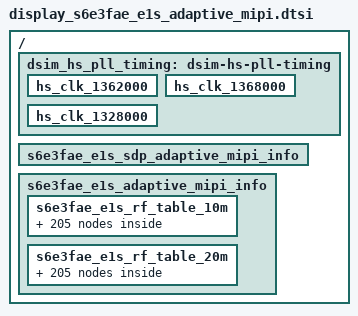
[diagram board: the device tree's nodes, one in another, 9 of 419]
/*
 * SAMSUNG Panel Device Tree Source
 *
 * Copyright (c) Samsung Electronics Co., Ltd.
 *		http://www.samsung.com
 *
 * This program is free software; you can redistribute it and/or modify
 * it under the terms of the GNU General Public License version 2 as
 * published by the Free Software Foundation.
 */

#include <dt-bindings/display/rf-band-id.h>

/ {
	fragment@freq_hop {
		target-path = "/";
		__overlay__ {
			dsim_hs_pll_timing: dsim-hs-pll-timing {
				hs_clk_1362000 {
					pmsk = <
						0x5 0x59 0x0 0xAC00
						0x00 0x00 0x0 0x0
						0x0 0x0 0x0 0x0
						0x0 0x0
						>;
					hs_clk = <1362000>;
				};

				hs_clk_1368000 {
					pmsk = <
						0x5 0x59 0x0 0x1000
						0x00 0x00 0x0 0x0
						0x0 0x0 0x0 0x0
						0x0 0x0
						>;
					hs_clk = <1368000>;
				};

				hs_clk_1328000 {
					pmsk = <
						0x5 0x56 0x0 0x7555
						0x00 0x00 0x0 0x0
						0x0 0x0 0x0 0x0
						0x0 0x0
						>;
					hs_clk = <1328000>;
				};
			}; 

			s6e3fae_e1s_sdp_adaptive_mipi_info:
			s6e3fae_e1s_sdp_adaptive_mipi_info {
				/* TABLE: ADAPTIVE MIPI V2: MIPI CLOCKS [kbps] */
				ADAPTIVE_MIPI_CLOCKS = <
					  1362000
					  1368000
					  1328000
				>;

				/* TABLE: ADAPTIVE MIPI V2: OSC CLOCKS [khz] */
				ADAPTIVE_OSC_CLOCKS = <
					  96500
					  94500
				>;

				/* TABLE: ADAPTIVE MIPI V2: TABLE_10M */
				/* RAT BAND FROM END RATING_A RATING_B RATING_C */
				ADAPTIVE_MIPI_V2_CLK_SEL_TABLE_10M = <
					1	1	0	0	0	0	0
					1	2	0	0	0	0	0
					1	3	0	0	0	63	0
					1	4	0	0	0	0	63
					2	11	10562	10754	0	0	0
					2	11	10755	10824	0	0	60
					2	11	10825	10838	0	0	0
					2	12	9662	9924	0	0	0
					2	12	9925	9938	0	0	60
					2	13	1162	1219	0	0	0
					2	13	1220	1289	0	0	60
					2	13	1290	1453	0	0	0
					2	13	1454	1494	60	0	0
					2	13	1495	1513	60	60	0
					2	14	1537	1729	0	0	0
					2	14	1730	1738	0	0	60
					2	15	4357	4458	0	0	0
					2	16	4387	4413	0	0	0
					2	17	2237	2369	0	0	0
					2	17	2370	2439	0	0	40
					2	17	2440	2563	0	0	0
					2	18	2937	3088	0	0	0
					2	29	712	763	0	0	0
					3	91	0	409	0	0	0
					3	91	410	549	0	0	60
					3	91	550	599	0	0	0
					3	92	600	1149	0	0	0
					3	92	1150	1199	0	0	60
					3	93	1200	1339	0	0	0
					3	93	1340	1479	0	0	60
					3	93	1480	1807	0	0	0
					3	93	1808	1889	60	0	0
					3	93	1890	1947	60	60	0
					3	93	1948	1949	0	60	0
					3	94	1950	2359	0	0	0
					3	94	2360	2399	0	0	60
					3	95	2400	2649	0	0	0
					3	97	2750	3039	0	0	0
					3	97	3040	3179	0	0	40
					3	97	3180	3449	0	0	0
					3	98	3450	3799	0	0	0
					3	102	5010	5179	0	0	0
					3	103	5180	5279	0	0	0
					3	104	5280	5379	0	0	0
					3	107	5730	5849	0	0	0
					3	108	5850	5869	0	140	0
					3	108	5870	5999	0	0	0
					3	109	6000	6149	0	0	0
					3	110	6150	6449	0	0	0
					3	111	6450	6500	0	0	60
					3	111	6501	6599	0	0	0
					3	115	8040	8589	0	0	0
					3	115	8590	8689	0	0	60
					3	116	8690	8719	0	140	0
					3	116	8720	9039	0	0	0
					3	118	9210	9659	0	0	0
					3	119	9660	9769	0	0	0
					3	120	9770	9869	0	0	0
					3	122	9920	10269	0	0	0
					3	122	10270	10359	0	0	60
					3	124	36200	36349	0	0	0
					3	128	37750	37769	0	40	0
					3	128	37770	38249	0	0	0
					3	129	38250	38329	0	60	0
					3	129	38330	38649	0	0	0
					3	130	38650	38819	0	0	0
					3	130	38820	38959	0	0	40
					3	130	38960	39414	0	0	0
					3	130	39415	39519	40	0	0
					3	130	39520	39554	40	40	0
					3	130	39555	39649	0	40	0
					3	131	39650	39659	0	0	40
					3	131	39660	40157	0	0	0
					3	131	40158	40269	40	0	0
					3	131	40270	40297	40	40	0
					3	131	40298	40409	0	40	0
					3	131	40410	41179	0	0	0
					3	131	41180	41319	0	0	40
					3	131	41320	41589	0	0	0
					3	132	41590	41710	40	0	0
					3	132	41711	41720	0	0	0
					3	132	41721	41860	0	40	0
					3	132	41861	42380	0	0	0
					3	132	42381	42520	0	0	40
					3	132	42521	43272	0	0	0
					3	132	43273	43412	40	0	0
					3	132	43413	43430	0	0	0
					3	132	43431	43570	0	40	0
					3	132	43571	43589	0	0	0
					3	138	55240	55422	0	0	0
					3	138	55423	55562	40	0	0
					3	138	55563	55580	0	0	0
					3	138	55581	55720	0	40	0
					3	138	55721	56190	0	0	0
					3	138	56191	56330	0	0	40
					3	138	56331	56739	0	0	0
					3	156	66436	66845	0	0	0
					3	156	66846	66985	0	0	60
					3	156	66986	67335	0	0	0
					3	161	68586	68935	0	0	0
					4	51	0	0	0	0	0
					4	52	0	0	27	63	0
					4	53	0	0	0	0	0
					4	54	0	0	0	69	0
					4	55	0	0	0	42	4
					4	56	0	0	0	63	0
					5	61	0	0	0	0	0
					5	62	0	0	0	0	63
					5	71	0	0	147	294	0
					7	256	422000	430180	0	0	0
					7	256	430181	432980	0	0	60
					7	256	432981	433980	0	0	0
					7	257	386000	396980	0	0	0
					7	257	396981	397980	0	0	60
					7	258	361000	363780	0	0	0
					7	258	363781	366580	0	0	60
					7	258	366581	373140	0	0	0
					7	258	373141	374780	60	0	0
					7	258	374781	375940	60	60	0
					7	258	375941	375980	0	60	0
					7	260	173800	178780	0	0	0
					7	262	524000	529780	0	0	0
					7	262	529781	532580	0	0	40
					7	262	532581	538000	0	0	0
					7	263	185000	191980	0	0	0
					7	267	145800	149200	0	0	0
					7	268	149200	151200	0	0	0
					7	269	151600	153580	0	0	0
					7	273	172000	172380	0	140	0
					7	273	172381	175000	0	0	0
					7	275	158200	164180	0	0	0
					7	280	386000	396980	0	0	0
					7	280	396981	398980	0	0	60
					7	281	171800	172380	0	140	0
					7	281	172381	178800	0	0	0
					7	283	151600	160580	0	0	0
					7	284	143400	145580	0	0	0
					7	285	470000	471980	0	0	0
					7	293	514000	514380	0	40	0
					7	293	514381	523980	0	0	0
					7	294	376000	377580	0	60	0
					7	294	377581	384000	0	0	0
					7	295	460000	463380	0	0	0
					7	295	463381	466180	0	0	40
					7	295	466181	475280	0	0	0
					7	295	475281	477380	40	0	0
					7	295	477381	478080	40	40	0
					7	295	478081	480000	0	40	0
					7	296	499200	499380	0	0	40
					7	296	499381	509340	0	0	0
					7	296	509341	511580	40	0	0
					7	296	511581	512140	40	40	0
					7	296	512141	514380	0	40	0
					7	296	514381	529780	0	0	0
					7	296	529781	532580	0	0	40
					7	296	532581	537980	0	0	0
					7	303	636667	637867	0	0	0
					7	303	637868	638807	20	0	0
					7	303	638808	638927	0	0	0
					7	303	638928	639847	0	20	0
					7	303	639848	642987	0	0	0
					7	303	642988	643927	0	0	20
					7	303	643928	646666	0	0	0
					7	321	422000	430180	0	0	0
					7	321	430181	432980	0	0	60
					7	321	432981	439980	0	0	0
					7	326	123400	130380	0	0	0
					7	332	620000	620860	0	0	0
					7	332	620861	621780	0	0	20
					7	332	621781	626520	0	0	0
					7	332	626521	627460	20	0	0
					7	332	627461	627520	0	0	0
					7	332	627521	628460	0	20	0
					7	332	628461	631920	0	0	0
					7	332	631921	632860	0	0	20
					7	332	632861	637880	0	0	0
					7	332	637881	638800	20	0	0
					7	332	638801	638920	0	0	0
					7	332	638921	639860	0	20	0
					7	332	639861	643000	0	0	0
					7	332	643001	643920	0	0	20
					7	332	643921	649220	0	0	0
					7	332	649221	650160	20	0	0
					7	332	650161	650320	0	0	0
					7	332	650321	651260	0	20	0
					7	332	651261	654060	0	0	0
					7	332	654061	654980	0	0	20
					7	332	654981	660580	0	0	0
					7	332	660581	661500	20	0	0
					7	332	661501	661720	0	0	0
					7	332	661721	662660	0	20	0
					7	332	662661	665120	0	0	0
					7	332	665121	666060	0	0	20
					7	332	666061	671920	0	0	0
					7	332	671921	672860	20	0	0
					7	332	672861	673120	0	0	0
					7	332	673121	674060	0	20	0
					7	332	674061	676200	0	0	0
					7	332	676201	677120	0	0	20
					7	332	677121	680000	0	0	0
					7	333	620000	620860	0	0	0
					7	333	620861	621780	0	0	20
					7	333	621781	626520	0	0	0
					7	333	626521	627460	20	0	0
					7	333	627461	627520	0	0	0
					7	333	627521	628460	0	20	0
					7	333	628461	631920	0	0	0
					7	333	631921	632860	0	0	20
					7	333	632861	637880	0	0	0
					7	333	637881	638800	20	0	0
					7	333	638801	638920	0	0	0
					7	333	638921	639860	0	20	0
					7	333	639861	643000	0	0	0
					7	333	643001	643920	0	0	20
					7	333	643921	649220	0	0	0
					7	333	649221	650160	20	0	0
					7	333	650161	650320	0	0	0
					7	333	650321	651260	0	20	0
					7	333	651261	653333	0	0	0
					7	334	693334	694634	0	0	0
					7	334	694635	695554	20	0	0
					7	334	695555	695934	0	0	0
					7	334	695935	696854	0	20	0
					7	334	696855	698334	0	0	0
					7	334	698335	699254	0	0	20
					7	334	699255	705974	0	0	0
					7	334	705975	706914	20	0	0
					7	334	706915	707334	0	0	0
					7	334	707335	708254	0	20	0
					7	334	708255	709394	0	0	0
					7	334	709395	710314	0	0	20
					7	334	710315	717334	0	0	0
					7	334	717335	718254	20	0	0
					7	334	718255	718734	0	0	0
					7	334	718735	719654	0	20	0
					7	334	719655	720454	0	0	0
					7	334	720455	721394	0	0	20
					7	334	721395	728674	0	0	0
					7	334	728675	729614	20	0	0
					7	334	729615	730134	0	0	0
					7	334	730135	731054	0	20	0
					7	334	731055	731534	0	0	0
					7	334	731535	732454	0	0	20
					7	334	732455	733333	0	0	0
					>;

				/* TABLE: ADAPTIVE MIPI V2: TABLE_20M */
				/* RAT BAND FROM END RATING_A RATING_B RATING_C */
				ADAPTIVE_MIPI_V2_CLK_SEL_TABLE_20M = <
					1	1	0	0	0	0	0
					1	2	0	0	0	0	0
					1	3	0	0	0	63	0
					1	4	0	0	0	0	63
					2	11	10562	10754	0	0	0
					2	11	10755	10824	0	0	60
					2	11	10825	10838	0	0	0
					2	12	9662	9924	0	0	0
					2	12	9925	9938	0	0	60
					2	13	1162	1219	0	0	0
					2	13	1220	1289	0	0	60
					2	13	1290	1453	0	0	0
					2	13	1454	1494	60	0	0
					2	13	1495	1513	60	60	0
					2	14	1537	1729	0	0	0
					2	14	1730	1738	0	0	60
					2	15	4357	4458	0	0	0
					2	16	4387	4413	0	0	0
					2	17	2237	2369	0	0	0
					2	17	2370	2439	0	0	40
					2	17	2440	2563	0	0	0
					2	18	2937	3088	0	0	0
					2	29	712	763	0	0	0
					3	91	0	359	0	0	0
					3	91	360	599	0	0	60
					3	92	600	1099	0	0	0
					3	92	1100	1199	0	0	60
					3	93	1200	1289	0	0	0
					3	93	1290	1529	0	0	60
					3	93	1530	1757	0	0	0
					3	93	1758	1839	60	0	0
					3	93	1840	1949	60	60	0
					3	94	1950	2309	0	0	0
					3	94	2310	2399	0	0	60
					3	95	2400	2649	0	0	0
					3	97	2750	2989	0	0	0
					3	97	2990	3229	0	0	40
					3	97	3230	3449	0	0	0
					3	98	3450	3799	0	0	0
					3	102	5010	5179	0	0	0
					3	103	5180	5279	0	0	0
					3	104	5280	5379	0	0	0
					3	107	5730	5849	0	0	0
					3	108	5850	5882	140	140	0
					3	108	5883	5919	0	140	0
					3	108	5920	5999	0	0	0
					3	109	6000	6149	0	0	0
					3	110	6150	6419	0	0	0
					3	110	6420	6449	0	0	140
					3	111	6450	6550	0	0	60
					3	111	6551	6599	0	0	0
					3	115	8040	8539	0	0	0
					3	115	8540	8689	0	0	60
					3	116	8690	8732	140	140	0
					3	116	8733	8769	0	140	0
					3	116	8770	9039	0	0	0
					3	118	9210	9659	0	0	0
					3	119	9660	9769	0	0	0
					3	120	9770	9869	0	0	0
					3	122	9920	10219	0	0	0
					3	122	10220	10359	0	0	60
					3	124	36200	36349	0	0	0
					3	128	37750	37819	0	40	0
					3	128	37820	38249	0	0	0
					3	129	38250	38297	60	60	0
					3	129	38298	38379	0	60	0
					3	129	38380	38649	0	0	0
					3	130	38650	38769	0	0	0
					3	130	38770	39009	0	0	40
					3	130	39010	39364	0	0	0
					3	130	39365	39469	40	0	0
					3	130	39470	39604	40	40	0
					3	130	39605	39649	0	40	0
					3	131	39650	39709	0	0	40
					3	131	39710	40107	0	0	0
					3	131	40108	40219	40	0	0
					3	131	40220	40347	40	40	0
					3	131	40348	40459	0	40	0
					3	131	40460	41129	0	0	0
					3	131	41130	41369	0	0	40
					3	131	41370	41589	0	0	0
					3	132	41590	41670	40	0	0
					3	132	41671	41760	40	40	0
					3	132	41761	41910	0	40	0
					3	132	41911	42330	0	0	0
					3	132	42331	42570	0	0	40
					3	132	42571	43222	0	0	0
					3	132	43223	43380	40	0	0
					3	132	43381	43462	40	40	0
					3	132	43463	43589	0	40	0
					3	138	55240	55372	0	0	0
					3	138	55373	55530	40	0	0
					3	138	55531	55612	40	40	0
					3	138	55613	55770	0	40	0
					3	138	55771	56140	0	0	0
					3	138	56141	56380	0	0	40
					3	138	56381	56739	0	0	0
					3	156	66436	66795	0	0	0
					3	156	66796	67035	0	0	60
					3	156	67036	67335	0	0	0
					3	161	68586	68935	0	0	0
					4	51	0	0	0	0	0
					4	52	0	0	27	63	0
					4	53	0	0	0	0	0
					4	54	0	0	6	69	0
					4	55	0	0	0	42	4
					4	56	0	0	0	63	0
					5	61	0	0	0	0	0
					5	62	0	0	0	0	63
					5	71	0	0	147	294	0
					7	256	422000	429180	0	0	0
					7	256	429181	433980	0	0	60
					7	257	386000	395980	0	0	0
					7	257	395981	397980	0	0	60
					7	258	361000	362780	0	0	0
					7	258	362781	367580	0	0	60
					7	258	367581	372140	0	0	0
					7	258	372141	373780	60	0	0
					7	258	373781	375980	60	60	0
					7	260	173800	178780	0	0	0
					7	262	524000	528780	0	0	0
					7	262	528781	533580	0	0	40
					7	262	533581	538000	0	0	0
					7	263	185000	191980	0	0	0
					7	267	145800	149200	0	0	0
					7	268	149200	151200	0	0	0
					7	269	151600	153580	0	0	0
					7	273	172000	172640	140	140	0
					7	273	172641	173380	0	140	0
					7	273	173381	175000	0	0	0
					7	275	158200	163580	0	0	0
					7	275	163581	164180	0	0	140
					7	280	386000	395980	0	0	0
					7	280	395981	398980	0	0	60
					7	281	171800	172640	140	140	0
					7	281	172641	173380	0	140	0
					7	281	173381	178800	0	0	0
					7	283	151600	160580	0	0	0
					7	284	143400	145580	0	0	0
					7	285	470000	471980	0	0	0
					7	293	514000	515380	0	40	0
					7	293	515381	523980	0	0	0
					7	294	376000	376940	60	60	0
					7	294	376941	378580	0	60	0
					7	294	378581	384000	0	0	0
					7	295	460000	462380	0	0	0
					7	295	462381	467180	0	0	40
					7	295	467181	474280	0	0	0
					7	295	474281	476380	40	0	0
					7	295	476381	479080	40	40	0
					7	295	479081	480000	0	40	0
					7	296	499200	500380	0	0	40
					7	296	500381	508340	0	0	0
					7	296	508341	510580	40	0	0
					7	296	510581	513140	40	40	0
					7	296	513141	515380	0	40	0
					7	296	515381	528780	0	0	0
					7	296	528781	533580	0	0	40
					7	296	533581	537980	0	0	0
					7	303	636667	637547	0	0	0
					7	303	637548	638587	20	0	0
					7	303	638588	639147	20	20	0
					7	303	639148	640187	0	20	0
					7	303	640188	642667	0	0	0
					7	303	642668	644247	0	0	20
					7	303	644248	646666	0	0	0
					7	321	422000	429180	0	0	0
					7	321	429181	433980	0	0	60
					7	321	433981	439980	0	0	0
					7	326	123400	130380	0	0	0
					7	332	620000	620520	0	0	0
					7	332	620521	622120	0	0	20
					7	332	622121	626200	0	0	0
					7	332	626201	627200	20	0	0
					7	332	627201	627780	20	20	0
					7	332	627781	628780	0	20	0
					7	332	628781	631600	0	0	0
					7	332	631601	633180	0	0	20
					7	332	633181	637540	0	0	0
					7	332	637541	638600	20	0	0
					7	332	638601	639140	20	20	0
					7	332	639141	640180	0	20	0
					7	332	640181	642660	0	0	0
					7	332	642661	644260	0	0	20
					7	332	644261	648900	0	0	0
					7	332	648901	650000	20	0	0
					7	332	650001	650480	20	20	0
					7	332	650481	651580	0	20	0
					7	332	651581	653720	0	0	0
					7	332	653721	655320	0	0	20
					7	332	655321	660240	0	0	0
					7	332	660241	661400	20	0	0
					7	332	661401	661840	20	20	0
					7	332	661841	662980	0	20	0
					7	332	662981	664800	0	0	0
					7	332	664801	666380	0	0	20
					7	332	666381	671600	0	0	0
					7	332	671601	672800	20	0	0
					7	332	672801	673180	20	20	0
					7	332	673181	674380	0	20	0
					7	332	674381	675860	0	0	0
					7	332	675861	677460	0	0	20
					7	332	677461	680000	0	0	0
					7	333	620000	620520	0	0	0
					7	333	620521	622120	0	0	20
					7	333	622121	626200	0	0	0
					7	333	626201	627200	20	0	0
					7	333	627201	627780	20	20	0
					7	333	627781	628780	0	20	0
					7	333	628781	631600	0	0	0
					7	333	631601	633180	0	0	20
					7	333	633181	637540	0	0	0
					7	333	637541	638600	20	0	0
					7	333	638601	639140	20	20	0
					7	333	639141	640180	0	20	0
					7	333	640181	642660	0	0	0
					7	333	642661	644260	0	0	20
					7	333	644261	648900	0	0	0
					7	333	648901	650000	20	0	0
					7	333	650001	650480	20	20	0
					7	333	650481	651580	0	20	0
					7	333	651581	653333	0	0	0
					7	334	693334	694294	0	0	0
					7	334	694295	695594	20	0	0
					7	334	695595	695894	20	20	0
					7	334	695895	697194	0	20	0
					7	334	697195	697994	0	0	0
					7	334	697995	699594	0	0	20
					7	334	699595	705634	0	0	0
					7	334	705635	706994	20	0	0
					7	334	706995	707234	20	20	0
					7	334	707235	708594	0	20	0
					7	334	708595	709054	0	0	0
					7	334	709055	710654	0	0	20
					7	334	710655	716994	0	0	0
					7	334	716995	718394	20	0	0
					7	334	718395	718594	20	20	0
					7	334	718595	719994	0	20	0
					7	334	719995	720134	0	0	0
					7	334	720135	721714	0	0	20
					7	334	721715	728334	0	0	0
					7	334	728335	729794	20	0	0
					7	334	729795	729934	20	20	0
					7	334	729935	731194	0	20	0
					7	334	731195	731394	0	20	20
					7	334	731395	732794	0	0	20
					7	334	732795	733333	0	0	0
					>;

				/* TABLE: ADAPTIVE MIPI V2: TABLE_OSC */
				/* RAT BAND FROM END OSC_IDX */
				ADAPTIVE_MIPI_V2_CLK_SEL_TABLE_OSC = <
					3	95	2400	2534	1
					3	98	3710	3799	1
					3	104	5280	5379	1
					3	108	5850	5999	1
					3	109	6000	6074	1
					3	116	8690	8924	1
					3	118	9210	9489	1
					7	260	175220	176480	1
					7	263	190181	191980	1
					7	269	151600	153580	1
					7	283	151600	157180	1
					>;
			};

			s6e3fae_e1s_adaptive_mipi_info:
			s6e3fae_e1s_adaptive_mipi_info {
				mipi_freq_lists = <1362 1368 1328>;
				ddi_osc_freq_lists = <1813>;
				rf_table_lists = <&s6e3fae_e1s_rf_table_10m &s6e3fae_e1s_rf_table_20m>;

				s6e3fae_e1s_rf_table_10m:
				s6e3fae_e1s_rf_table_10m {
					tb1 { id = <GSM850>; range = <0 0>; rating = <0 0 0>; };
					tb2 { id = <EGSM900>; range = <0 0>; rating = <0 0 0>; };
					tb3 { id = <DCS1800>; range = <0 0>; rating = <0 4 0>; };
					tb4 { id = <PCS1900>; range = <0 0>; rating = <0 0 80>; };
					tb5 { id = <WB01>; range = <10562 10754>; rating = <0 0 0>; };
					tb6 { id = <WB01>; range = <10755 10824>; rating = <0 0 4>; };
					tb7 { id = <WB01>; range = <10825 10838>; rating = <0 0 0>; };
					tb8 { id = <WB02>; range = <9662 9924>; rating = <0 0 0>; };
					tb9 { id = <WB02>; range = <9925 9938>; rating = <0 0 80>; };
					tb10 { id = <WB03>; range = <1162 1219>; rating = <0 0 0>; };
					tb11 { id = <WB03>; range = <1220 1289>; rating = <0 0 4>; };
					tb12 { id = <WB03>; range = <1290 1453>; rating = <0 0 0>; };
					tb13 { id = <WB03>; range = <1454 1494>; rating = <4 0 0>; };
					tb14 { id = <WB03>; range = <1495 1513>; rating = <4 4 0>; };
					tb15 { id = <WB04>; range = <1537 1729>; rating = <0 0 0>; };
					tb16 { id = <WB04>; range = <1730 1738>; rating = <0 0 4>; };
					tb17 { id = <WB05>; range = <4357 4458>; rating = <0 0 0>; };
					tb18 { id = <WB06>; range = <4387 4413>; rating = <0 0 0>; };
					tb19 { id = <WB07>; range = <2237 2369>; rating = <0 0 0>; };
					tb20 { id = <WB07>; range = <2370 2439>; rating = <0 0 40>; };
					tb21 { id = <WB07>; range = <2440 2563>; rating = <0 0 0>; };
					tb22 { id = <WB08>; range = <2937 3088>; rating = <0 0 0>; };
					tb23 { id = <WB19>; range = <712 763>; rating = <0 0 0>; };
					tb24 { id = <LB01>; range = <0 409>; rating = <0 0 0>; };
					tb25 { id = <LB01>; range = <410 549>; rating = <0 0 4>; };
					tb26 { id = <LB01>; range = <550 599>; rating = <0 0 0>; };
					tb27 { id = <LB02>; range = <600 1149>; rating = <0 0 0>; };
					tb28 { id = <LB02>; range = <1150 1199>; rating = <0 0 80>; };
					tb29 { id = <LB03>; range = <1200 1339>; rating = <0 0 0>; };
					tb30 { id = <LB03>; range = <1340 1479>; rating = <0 0 4>; };
					tb31 { id = <LB03>; range = <1480 1807>; rating = <0 0 0>; };
					tb32 { id = <LB03>; range = <1808 1889>; rating = <4 0 0>; };
					tb33 { id = <LB03>; range = <1890 1947>; rating = <4 4 0>; };
					tb34 { id = <LB03>; range = <1948 1949>; rating = <0 4 0>; };
					tb35 { id = <LB04>; range = <1950 2359>; rating = <0 0 0>; };
					tb36 { id = <LB04>; range = <2360 2399>; rating = <0 0 4>; };
					tb37 { id = <LB05>; range = <2400 2649>; rating = <0 0 0>; };
					tb38 { id = <LB07>; range = <2750 3039>; rating = <0 0 0>; };
					tb39 { id = <LB07>; range = <3040 3179>; rating = <0 0 40>; };
					tb40 { id = <LB07>; range = <3180 3449>; rating = <0 0 0>; };
					tb41 { id = <LB08>; range = <3450 3799>; rating = <0 0 0>; };
					tb42 { id = <LB12>; range = <5010 5179>; rating = <0 0 0>; };
					tb43 { id = <LB13>; range = <5180 5279>; rating = <0 0 0>; };
					tb44 { id = <LB14>; range = <5280 5379>; rating = <0 0 0>; };
					tb45 { id = <LB17>; range = <5730 5849>; rating = <0 0 0>; };
					tb46 { id = <LB18>; range = <5850 5869>; rating = <0 6 0>; };
					tb47 { id = <LB18>; range = <5870 5999>; rating = <0 0 0>; };
					tb48 { id = <LB19>; range = <6000 6149>; rating = <0 0 0>; };
					tb49 { id = <LB20>; range = <6150 6449>; rating = <0 0 0>; };
					tb50 { id = <LB21>; range = <6450 6500>; rating = <0 0 4>; };
					tb51 { id = <LB21>; range = <6501 6599>; rating = <0 0 0>; };
					tb52 { id = <LB25>; range = <8040 8589>; rating = <0 0 0>; };
					tb53 { id = <LB25>; range = <8590 8689>; rating = <0 0 80>; };
					tb54 { id = <LB26>; range = <8690 8719>; rating = <0 6 0>; };
					tb55 { id = <LB26>; range = <8720 9039>; rating = <0 0 0>; };
					tb56 { id = <LB28>; range = <9210 9659>; rating = <0 0 0>; };
					tb57 { id = <LB29>; range = <9660 9769>; rating = <0 0 0>; };
					tb58 { id = <LB30>; range = <9770 9869>; rating = <0 0 0>; };
					tb59 { id = <LB32>; range = <9920 10269>; rating = <0 0 0>; };
					tb60 { id = <LB32>; range = <10270 10359>; rating = <0 0 4>; };
					tb61 { id = <LB34>; range = <36200 36349>; rating = <0 0 0>; };
					tb62 { id = <LB38>; range = <37750 37769>; rating = <0 2 0>; };
					tb63 { id = <LB38>; range = <37770 38249>; rating = <0 0 0>; };
					tb64 { id = <LB39>; range = <38250 38329>; rating = <0 4 0>; };
					tb65 { id = <LB39>; range = <38330 38649>; rating = <0 0 0>; };
					tb66 { id = <LB40>; range = <38650 39649>; rating = <0 0 0>; };
					tb67 { id = <LB41>; range = <39650 39659>; rating = <0 0 2>; };
					tb68 { id = <LB41>; range = <39660 40157>; rating = <0 0 0>; };
					tb69 { id = <LB41>; range = <40158 40269>; rating = <2 0 0>; };
					tb70 { id = <LB41>; range = <40270 40297>; rating = <2 2 0>; };
					tb71 { id = <LB41>; range = <40298 40409>; rating = <0 2 0>; };
					tb72 { id = <LB41>; range = <40410 41179>; rating = <0 0 0>; };
					tb73 { id = <LB41>; range = <41180 41319>; rating = <0 0 40>; };
					tb74 { id = <LB41>; range = <41320 41589>; rating = <0 0 0>; };
					tb75 { id = <LB42>; range = <41590 41710>; rating = <40 0 0>; };
					tb76 { id = <LB42>; range = <41711 41720>; rating = <0 0 0>; };
					tb77 { id = <LB42>; range = <41721 41860>; rating = <0 40 0>; };
					tb78 { id = <LB42>; range = <41861 42380>; rating = <0 0 0>; };
					tb79 { id = <LB42>; range = <42381 42520>; rating = <0 0 2>; };
					tb80 { id = <LB42>; range = <42521 43272>; rating = <0 0 0>; };
					tb81 { id = <LB42>; range = <43273 43412>; rating = <2 0 0>; };
					tb82 { id = <LB42>; range = <43413 43430>; rating = <0 0 0>; };
					tb83 { id = <LB42>; range = <43431 43570>; rating = <0 2 0>; };
					tb84 { id = <LB42>; range = <43571 43589>; rating = <0 0 0>; };
					tb85 { id = <LB48>; range = <55240 55422>; rating = <0 0 0>; };
					tb86 { id = <LB48>; range = <55423 55562>; rating = <2 0 0>; };
					tb87 { id = <LB48>; range = <55563 55580>; rating = <0 0 0>; };
					tb88 { id = <LB48>; range = <55581 55720>; rating = <0 2 0>; };
					tb89 { id = <LB48>; range = <55721 56739>; rating = <0 0 0>; };
					tb90 { id = <LB66>; range = <66436 66845>; rating = <0 0 0>; };
					tb91 { id = <LB66>; range = <66846 66985>; rating = <0 0 4>; };
					tb92 { id = <LB66>; range = <66986 67335>; rating = <0 0 0>; };
					tb93 { id = <LB71>; range = <68586 68935>; rating = <0 0 0>; };
					tb94 { id = <TD1>; range = <0 0>; rating = <0 0 0>; };
					tb95 { id = <TD2>; range = <0 0>; rating = <2 4 0>; };
					tb96 { id = <TD3>; range = <0 0>; rating = <0 0 0>; };
					tb97 { id = <TD4>; range = <0 0>; rating = <0 6 0>; };
					tb98 { id = <TD5>; range = <0 0>; rating = <0 0 1>; };
					tb99 { id = <TD6>; range = <0 0>; rating = <0 4 0>; };
					tb100 { id = <BC0>; range = <0 0>; rating = <0 0 0>; };
					tb101 { id = <BC1>; range = <0 0>; rating = <0 0 80>; };
					tb102 { id = <BC10>; range = <0 0>; rating = <6 12 0>; };
					tb103 { id = <N001>; range = <422000 430180>; rating = <0 0 0>; };
					tb104 { id = <N001>; range = <430181 432980>; rating = <0 0 4>; };
					tb105 { id = <N001>; range = <432981 433980>; rating = <0 0 0>; };
					tb106 { id = <N002>; range = <386000 396980>; rating = <0 0 0>; };
					tb107 { id = <N002>; range = <396981 397980>; rating = <0 0 80>; };
					tb108 { id = <N003>; range = <361000 363780>; rating = <0 0 0>; };
					tb109 { id = <N003>; range = <363781 366580>; rating = <0 0 4>; };
					tb110 { id = <N003>; range = <366581 373140>; rating = <0 0 0>; };
					tb111 { id = <N003>; range = <373141 374780>; rating = <4 0 0>; };
					tb112 { id = <N003>; range = <374781 375940>; rating = <4 4 0>; };
					tb113 { id = <N003>; range = <375941 375980>; rating = <0 4 0>; };
					tb114 { id = <N005>; range = <173800 178780>; rating = <0 0 0>; };
					tb115 { id = <N007>; range = <524000 529780>; rating = <0 0 0>; };
					tb116 { id = <N007>; range = <529781 532580>; rating = <0 0 40>; };
					tb117 { id = <N007>; range = <532581 538000>; rating = <0 0 0>; };
					tb118 { id = <N008>; range = <185000 191980>; rating = <0 0 0>; };
					tb119 { id = <N012>; range = <145800 149200>; rating = <0 0 0>; };
					tb120 { id = <N014>; range = <151600 153580>; rating = <0 0 0>; };
					tb121 { id = <N020>; range = <158200 164180>; rating = <0 0 0>; };
					tb122 { id = <N025>; range = <386000 396980>; rating = <0 0 0>; };
					tb123 { id = <N025>; range = <396981 398980>; rating = <0 0 80>; };
					tb124 { id = <N028>; range = <151600 160580>; rating = <0 0 0>; };
					tb125 { id = <N029>; range = <143400 145580>; rating = <0 0 0>; };
					tb126 { id = <N030>; range = <470000 471980>; rating = <0 0 0>; };
					tb127 { id = <N038>; range = <514000 514380>; rating = <0 2 0>; };
					tb128 { id = <N038>; range = <514381 523980>; rating = <0 0 0>; };
					tb129 { id = <N040>; range = <460000 480000>; rating = <0 0 0>; };
					tb130 { id = <N041>; range = <499200 499380>; rating = <0 0 2>; };
					tb131 { id = <N041>; range = <499381 509340>; rating = <0 0 0>; };
					tb132 { id = <N041>; range = <509341 511580>; rating = <2 0 0>; };
					tb133 { id = <N041>; range = <511581 512140>; rating = <2 2 0>; };
					tb134 { id = <N041>; range = <512141 514380>; rating = <0 2 0>; };
					tb135 { id = <N041>; range = <514381 529780>; rating = <0 0 0>; };
					tb136 { id = <N041>; range = <529781 532580>; rating = <0 0 40>; };
					tb137 { id = <N041>; range = <532581 537980>; rating = <0 0 0>; };
					tb138 { id = <N048>; range = <636667 637867>; rating = <0 0 0>; };
					tb139 { id = <N048>; range = <637868 638807>; rating = <2 0 0>; };
					tb140 { id = <N048>; range = <638808 638927>; rating = <0 0 0>; };
					tb141 { id = <N048>; range = <638928 639847>; rating = <0 2 0>; };
					tb142 { id = <N048>; range = <639848 646666>; rating = <0 0 0>; };
					tb143 { id = <N066>; range = <422000 430180>; rating = <0 0 0>; };
					tb144 { id = <N066>; range = <430181 432980>; rating = <0 0 4>; };
					tb145 { id = <N066>; range = <432981 439980>; rating = <0 0 0>; };
					tb146 { id = <N071>; range = <123400 130380>; rating = <0 0 0>; };
					tb147 { id = <N077>; range = <620000 620860>; rating = <0 0 0>; };
					tb148 { id = <N077>; range = <620861 621780>; rating = <0 0 40>; };
					tb149 { id = <N077>; range = <621781 626520>; rating = <0 0 0>; };
					tb150 { id = <N077>; range = <626521 627460>; rating = <40 0 0>; };
					tb151 { id = <N077>; range = <627461 627520>; rating = <0 0 0>; };
					tb152 { id = <N077>; range = <627521 628460>; rating = <0 40 0>; };
					tb153 { id = <N077>; range = <628461 631920>; rating = <0 0 0>; };
					tb154 { id = <N077>; range = <631921 632860>; rating = <0 0 2>; };
					tb155 { id = <N077>; range = <632861 637880>; rating = <0 0 0>; };
					tb156 { id = <N077>; range = <637881 638800>; rating = <2 0 0>; };
					tb157 { id = <N077>; range = <638801 638920>; rating = <0 0 0>; };
					tb158 { id = <N077>; range = <638921 639860>; rating = <0 2 0>; };
					tb159 { id = <N077>; range = <639861 654060>; rating = <0 0 0>; };
					tb160 { id = <N077>; range = <654061 654980>; rating = <0 0 2>; };
					tb161 { id = <N077>; range = <654981 660580>; rating = <0 0 0>; };
					tb162 { id = <N077>; range = <660581 661500>; rating = <2 0 0>; };
					tb163 { id = <N077>; range = <661501 661720>; rating = <0 0 0>; };
					tb164 { id = <N077>; range = <661721 662660>; rating = <0 2 0>; };
					tb165 { id = <N077>; range = <662661 665120>; rating = <0 0 0>; };
					tb166 { id = <N077>; range = <665121 666060>; rating = <0 0 40>; };
					tb167 { id = <N077>; range = <666061 671920>; rating = <0 0 0>; };
					tb168 { id = <N077>; range = <671921 672860>; rating = <40 0 0>; };
					tb169 { id = <N077>; range = <672861 673120>; rating = <0 0 0>; };
					tb170 { id = <N077>; range = <673121 674060>; rating = <0 40 0>; };
					tb171 { id = <N077>; range = <674061 676200>; rating = <0 0 0>; };
					tb172 { id = <N077>; range = <676201 677120>; rating = <0 0 2>; };
					tb173 { id = <N077>; range = <677121 680000>; rating = <0 0 0>; };
					tb174 { id = <N078>; range = <620000 620860>; rating = <0 0 0>; };
					tb175 { id = <N078>; range = <620861 621780>; rating = <0 0 40>; };
					tb176 { id = <N078>; range = <621781 626520>; rating = <0 0 0>; };
					tb177 { id = <N078>; range = <626521 627460>; rating = <40 0 0>; };
					tb178 { id = <N078>; range = <627461 627520>; rating = <0 0 0>; };
					tb179 { id = <N078>; range = <627521 628460>; rating = <0 40 0>; };
					tb180 { id = <N078>; range = <628461 631920>; rating = <0 0 0>; };
					tb181 { id = <N078>; range = <631921 632860>; rating = <0 0 2>; };
					tb182 { id = <N078>; range = <632861 637880>; rating = <0 0 0>; };
					tb183 { id = <N078>; range = <637881 638800>; rating = <2 0 0>; };
					tb184 { id = <N078>; range = <638801 638920>; rating = <0 0 0>; };
					tb185 { id = <N078>; range = <638921 639860>; rating = <0 2 0>; };
					tb186 { id = <N078>; range = <639861 653333>; rating = <0 0 0>; };
					tb187 { id = <N079>; range = <693334 698334>; rating = <0 0 0>; };
					tb188 { id = <N079>; range = <698335 699254>; rating = <0 0 2>; };
					tb189 { id = <N079>; range = <699255 705974>; rating = <0 0 0>; };
					tb190 { id = <N079>; range = <705975 706914>; rating = <2 0 0>; };
					tb191 { id = <N079>; range = <706915 707334>; rating = <0 0 0>; };
					tb192 { id = <N079>; range = <707335 708254>; rating = <0 2 0>; };
					tb193 { id = <N079>; range = <708255 709394>; rating = <0 0 0>; };
					tb194 { id = <N079>; range = <709395 710314>; rating = <0 0 40>; };
					tb195 { id = <N079>; range = <710315 717334>; rating = <0 0 0>; };
					tb196 { id = <N079>; range = <717335 718254>; rating = <40 0 0>; };
					tb197 { id = <N079>; range = <718255 718734>; rating = <0 0 0>; };
					tb198 { id = <N079>; range = <718735 719654>; rating = <0 40 0>; };
					tb199 { id = <N079>; range = <719655 720454>; rating = <0 0 0>; };
					tb200 { id = <N079>; range = <720455 721394>; rating = <0 0 2>; };
					tb201 { id = <N079>; range = <721395 728674>; rating = <0 0 0>; };
					tb202 { id = <N079>; range = <728675 729614>; rating = <2 0 0>; };
					tb203 { id = <N079>; range = <729615 730134>; rating = <0 0 0>; };
					tb204 { id = <N079>; range = <730135 731054>; rating = <0 2 0>; };
					tb205 { id = <N079>; range = <731055 733333>; rating = <0 0 0>; };
				};

				s6e3fae_e1s_rf_table_20m:
				s6e3fae_e1s_rf_table_20m {
					tb1 { id = <GSM850>; range = <0 0>; rating = <0 0 0>; };
					tb2 { id = <EGSM900>; range = <0 0>; rating = <0 0 0>; };
					tb3 { id = <DCS1800>; range = <0 0>; rating = <0 4 0>; };
					tb4 { id = <PCS1900>; range = <0 0>; rating = <0 0 80>; };
					tb5 { id = <WB01>; range = <10562 10754>; rating = <0 0 0>; };
					tb6 { id = <WB01>; range = <10755 10824>; rating = <0 0 4>; };
					tb7 { id = <WB01>; range = <10825 10838>; rating = <0 0 0>; };
					tb8 { id = <WB02>; range = <9662 9924>; rating = <0 0 0>; };
					tb9 { id = <WB02>; range = <9925 9938>; rating = <0 0 80>; };
					tb10 { id = <WB03>; range = <1162 1219>; rating = <0 0 0>; };
					tb11 { id = <WB03>; range = <1220 1289>; rating = <0 0 4>; };
					tb12 { id = <WB03>; range = <1290 1453>; rating = <0 0 0>; };
					tb13 { id = <WB03>; range = <1454 1494>; rating = <4 0 0>; };
					tb14 { id = <WB03>; range = <1495 1513>; rating = <4 4 0>; };
					tb15 { id = <WB04>; range = <1537 1729>; rating = <0 0 0>; };
					tb16 { id = <WB04>; range = <1730 1738>; rating = <0 0 4>; };
					tb17 { id = <WB05>; range = <4357 4458>; rating = <0 0 0>; };
					tb18 { id = <WB06>; range = <4387 4413>; rating = <0 0 0>; };
					tb19 { id = <WB07>; range = <2237 2369>; rating = <0 0 0>; };
					tb20 { id = <WB07>; range = <2370 2439>; rating = <0 0 40>; };
					tb21 { id = <WB07>; range = <2440 2563>; rating = <0 0 0>; };
					tb22 { id = <WB08>; range = <2937 3088>; rating = <0 0 0>; };
					tb23 { id = <WB19>; range = <712 763>; rating = <0 0 0>; };
					tb24 { id = <LB01>; range = <0 359>; rating = <0 0 0>; };
					tb25 { id = <LB01>; range = <360 599>; rating = <0 0 4>; };
					tb26 { id = <LB02>; range = <600 1099>; rating = <0 0 0>; };
					tb27 { id = <LB02>; range = <1100 1199>; rating = <0 0 80>; };
					tb28 { id = <LB03>; range = <1200 1289>; rating = <0 0 0>; };
					tb29 { id = <LB03>; range = <1290 1529>; rating = <0 0 4>; };
					tb30 { id = <LB03>; range = <1530 1757>; rating = <0 0 0>; };
					tb31 { id = <LB03>; range = <1758 1839>; rating = <4 0 0>; };
					tb32 { id = <LB03>; range = <1840 1949>; rating = <4 4 0>; };
					tb33 { id = <LB04>; range = <1950 2309>; rating = <0 0 0>; };
					tb34 { id = <LB04>; range = <2310 2399>; rating = <0 0 4>; };
					tb35 { id = <LB05>; range = <2400 2649>; rating = <0 0 0>; };
					tb36 { id = <LB07>; range = <2750 2989>; rating = <0 0 0>; };
					tb37 { id = <LB07>; range = <2990 3229>; rating = <0 0 40>; };
					tb38 { id = <LB07>; range = <3230 3449>; rating = <0 0 0>; };
					tb39 { id = <LB08>; range = <3450 3799>; rating = <0 0 0>; };
					tb40 { id = <LB12>; range = <5010 5179>; rating = <0 0 0>; };
					tb41 { id = <LB13>; range = <5180 5279>; rating = <0 0 0>; };
					tb42 { id = <LB14>; range = <5280 5379>; rating = <0 0 0>; };
					tb43 { id = <LB17>; range = <5730 5849>; rating = <0 0 0>; };
					tb44 { id = <LB18>; range = <5850 5882>; rating = <6 6 0>; };
					tb45 { id = <LB18>; range = <5883 5919>; rating = <0 6 0>; };
					tb46 { id = <LB18>; range = <5920 5999>; rating = <0 0 0>; };
					tb47 { id = <LB19>; range = <6000 6149>; rating = <0 0 0>; };
					tb48 { id = <LB20>; range = <6150 6419>; rating = <0 0 0>; };
					tb49 { id = <LB20>; range = <6420 6449>; rating = <0 0 6>; };
					tb50 { id = <LB21>; range = <6450 6550>; rating = <0 0 4>; };
					tb51 { id = <LB21>; range = <6551 6599>; rating = <0 0 0>; };
					tb52 { id = <LB25>; range = <8040 8539>; rating = <0 0 0>; };
					tb53 { id = <LB25>; range = <8540 8689>; rating = <0 0 80>; };
					tb54 { id = <LB26>; range = <8690 8732>; rating = <6 6 0>; };
					tb55 { id = <LB26>; range = <8733 8769>; rating = <0 6 0>; };
					tb56 { id = <LB26>; range = <8770 9039>; rating = <0 0 0>; };
					tb57 { id = <LB28>; range = <9210 9659>; rating = <0 0 0>; };
					tb58 { id = <LB29>; range = <9660 9769>; rating = <0 0 0>; };
					tb59 { id = <LB30>; range = <9770 9869>; rating = <0 0 0>; };
					tb60 { id = <LB32>; range = <9920 10219>; rating = <0 0 0>; };
					tb61 { id = <LB32>; range = <10220 10359>; rating = <0 0 4>; };
					tb62 { id = <LB34>; range = <36200 36349>; rating = <0 0 0>; };
					tb63 { id = <LB38>; range = <37750 37819>; rating = <0 2 0>; };
					tb64 { id = <LB38>; range = <37820 38249>; rating = <0 0 0>; };
					tb65 { id = <LB39>; range = <38250 38297>; rating = <4 4 0>; };
					tb66 { id = <LB39>; range = <38298 38379>; rating = <0 4 0>; };
					tb67 { id = <LB39>; range = <38380 38649>; rating = <0 0 0>; };
					tb68 { id = <LB40>; range = <38650 39649>; rating = <0 0 0>; };
					tb69 { id = <LB41>; range = <39650 39709>; rating = <0 0 2>; };
					tb70 { id = <LB41>; range = <39710 40107>; rating = <0 0 0>; };
					tb71 { id = <LB41>; range = <40108 40219>; rating = <2 0 0>; };
					tb72 { id = <LB41>; range = <40220 40347>; rating = <2 2 0>; };
					tb73 { id = <LB41>; range = <40348 40459>; rating = <0 2 0>; };
					tb74 { id = <LB41>; range = <40460 41129>; rating = <0 0 0>; };
					tb75 { id = <LB41>; range = <41130 41369>; rating = <0 0 40>; };
					tb76 { id = <LB41>; range = <41370 41589>; rating = <0 0 0>; };
					tb77 { id = <LB42>; range = <41590 41670>; rating = <40 0 0>; };
					tb78 { id = <LB42>; range = <41671 41760>; rating = <40 40 0>; };
					tb79 { id = <LB42>; range = <41761 41910>; rating = <0 40 0>; };
					tb80 { id = <LB42>; range = <41911 42330>; rating = <0 0 0>; };
					tb81 { id = <LB42>; range = <42331 42570>; rating = <0 0 2>; };
					tb82 { id = <LB42>; range = <42571 43222>; rating = <0 0 0>; };
					tb83 { id = <LB42>; range = <43223 43380>; rating = <2 0 0>; };
					tb84 { id = <LB42>; range = <43381 43462>; rating = <2 2 0>; };
					tb85 { id = <LB42>; range = <43463 43589>; rating = <0 2 0>; };
					tb86 { id = <LB48>; range = <55240 55372>; rating = <0 0 0>; };
					tb87 { id = <LB48>; range = <55373 55530>; rating = <2 0 0>; };
					tb88 { id = <LB48>; range = <55531 55612>; rating = <2 2 0>; };
					tb89 { id = <LB48>; range = <55613 55770>; rating = <0 2 0>; };
					tb90 { id = <LB48>; range = <55771 56739>; rating = <0 0 0>; };
					tb91 { id = <LB66>; range = <66436 66795>; rating = <0 0 0>; };
					tb92 { id = <LB66>; range = <66796 67035>; rating = <0 0 4>; };
					tb93 { id = <LB66>; range = <67036 67335>; rating = <0 0 0>; };
					tb94 { id = <LB71>; range = <68586 68935>; rating = <0 0 0>; };
					tb95 { id = <TD1>; range = <0 0>; rating = <0 0 0>; };
					tb96 { id = <TD2>; range = <0 0>; rating = <2 4 0>; };
					tb97 { id = <TD3>; range = <0 0>; rating = <0 0 0>; };
					tb98 { id = <TD4>; range = <0 0>; rating = <2 6 0>; };
					tb99 { id = <TD5>; range = <0 0>; rating = <0 0 1>; };
					tb100 { id = <TD6>; range = <0 0>; rating = <0 4 0>; };
					tb101 { id = <BC0>; range = <0 0>; rating = <0 0 0>; };
					tb102 { id = <BC1>; range = <0 0>; rating = <0 0 80>; };
					tb103 { id = <BC10>; range = <0 0>; rating = <6 12 0>; };
					tb104 { id = <N001>; range = <422000 429180>; rating = <0 0 0>; };
					tb105 { id = <N001>; range = <429181 433980>; rating = <0 0 4>; };
					tb106 { id = <N002>; range = <386000 395980>; rating = <0 0 0>; };
					tb107 { id = <N002>; range = <395981 397980>; rating = <0 0 80>; };
					tb108 { id = <N003>; range = <361000 362780>; rating = <0 0 0>; };
					tb109 { id = <N003>; range = <362781 367580>; rating = <0 0 4>; };
					tb110 { id = <N003>; range = <367581 372140>; rating = <0 0 0>; };
					tb111 { id = <N003>; range = <372141 373780>; rating = <4 0 0>; };
					tb112 { id = <N003>; range = <373781 375980>; rating = <4 4 0>; };
					tb113 { id = <N005>; range = <173800 178780>; rating = <0 0 0>; };
					tb114 { id = <N007>; range = <524000 528780>; rating = <0 0 0>; };
					tb115 { id = <N007>; range = <528781 533580>; rating = <0 0 40>; };
					tb116 { id = <N007>; range = <533581 538000>; rating = <0 0 0>; };
					tb117 { id = <N008>; range = <185000 191980>; rating = <0 0 0>; };
					tb118 { id = <N012>; range = <145800 149200>; rating = <0 0 0>; };
					tb119 { id = <N014>; range = <151600 153580>; rating = <0 0 0>; };
					tb120 { id = <N020>; range = <158200 163580>; rating = <0 0 0>; };
					tb121 { id = <N020>; range = <163581 164180>; rating = <0 0 6>; };
					tb122 { id = <N025>; range = <386000 395980>; rating = <0 0 0>; };
					tb123 { id = <N025>; range = <395981 398980>; rating = <0 0 80>; };
					tb124 { id = <N028>; range = <151600 160580>; rating = <0 0 0>; };
					tb125 { id = <N029>; range = <143400 145580>; rating = <0 0 0>; };
					tb126 { id = <N030>; range = <470000 471980>; rating = <0 0 0>; };
					tb127 { id = <N038>; range = <514000 515380>; rating = <0 2 0>; };
					tb128 { id = <N038>; range = <515381 523980>; rating = <0 0 0>; };
					tb129 { id = <N040>; range = <460000 480000>; rating = <0 0 0>; };
					tb130 { id = <N041>; range = <499200 500380>; rating = <0 0 2>; };
					tb131 { id = <N041>; range = <500381 508340>; rating = <0 0 0>; };
					tb132 { id = <N041>; range = <508341 510580>; rating = <2 0 0>; };
					tb133 { id = <N041>; range = <510581 513140>; rating = <2 2 0>; };
					tb134 { id = <N041>; range = <513141 515380>; rating = <0 2 0>; };
					tb135 { id = <N041>; range = <515381 528780>; rating = <0 0 0>; };
					tb136 { id = <N041>; range = <528781 533580>; rating = <0 0 40>; };
					tb137 { id = <N041>; range = <533581 537980>; rating = <0 0 0>; };
					tb138 { id = <N048>; range = <636667 637547>; rating = <0 0 0>; };
					tb139 { id = <N048>; range = <637548 638587>; rating = <2 0 0>; };
					tb140 { id = <N048>; range = <638588 639147>; rating = <2 2 0>; };
					tb141 { id = <N048>; range = <639148 640187>; rating = <0 2 0>; };
					tb142 { id = <N048>; range = <640188 646666>; rating = <0 0 0>; };
					tb143 { id = <N066>; range = <422000 429180>; rating = <0 0 0>; };
					tb144 { id = <N066>; range = <429181 433980>; rating = <0 0 4>; };
					tb145 { id = <N066>; range = <433981 439980>; rating = <0 0 0>; };
					tb146 { id = <N071>; range = <123400 130380>; rating = <0 0 0>; };
					tb147 { id = <N077>; range = <620000 620520>; rating = <0 0 0>; };
					tb148 { id = <N077>; range = <620521 622120>; rating = <0 0 40>; };
					tb149 { id = <N077>; range = <622121 626200>; rating = <0 0 0>; };
					tb150 { id = <N077>; range = <626201 627200>; rating = <40 0 0>; };
					tb151 { id = <N077>; range = <627201 627780>; rating = <40 40 0>; };
					tb152 { id = <N077>; range = <627781 628780>; rating = <0 40 0>; };
					tb153 { id = <N077>; range = <628781 631600>; rating = <0 0 0>; };
					tb154 { id = <N077>; range = <631601 633180>; rating = <0 0 2>; };
					tb155 { id = <N077>; range = <633181 637540>; rating = <0 0 0>; };
					tb156 { id = <N077>; range = <637541 638600>; rating = <2 0 0>; };
					tb157 { id = <N077>; range = <638601 639140>; rating = <2 2 0>; };
					tb158 { id = <N077>; range = <639141 640180>; rating = <0 2 0>; };
					tb159 { id = <N077>; range = <640181 653720>; rating = <0 0 0>; };
					tb160 { id = <N077>; range = <653721 655320>; rating = <0 0 2>; };
					tb161 { id = <N077>; range = <655321 660240>; rating = <0 0 0>; };
					tb162 { id = <N077>; range = <660241 661400>; rating = <2 0 0>; };
					tb163 { id = <N077>; range = <661401 661840>; rating = <2 2 0>; };
					tb164 { id = <N077>; range = <661841 662980>; rating = <0 2 0>; };
					tb165 { id = <N077>; range = <662981 664800>; rating = <0 0 0>; };
					tb166 { id = <N077>; range = <664801 666380>; rating = <0 0 40>; };
					tb167 { id = <N077>; range = <666381 671600>; rating = <0 0 0>; };
					tb168 { id = <N077>; range = <671601 672800>; rating = <40 0 0>; };
					tb169 { id = <N077>; range = <672801 673180>; rating = <40 40 0>; };
					tb170 { id = <N077>; range = <673181 674380>; rating = <0 40 0>; };
					tb171 { id = <N077>; range = <674381 675860>; rating = <0 0 0>; };
					tb172 { id = <N077>; range = <675861 677460>; rating = <0 0 2>; };
					tb173 { id = <N077>; range = <677461 680000>; rating = <0 0 0>; };
					tb174 { id = <N078>; range = <620000 620520>; rating = <0 0 0>; };
					tb175 { id = <N078>; range = <620521 622120>; rating = <0 0 40>; };
					tb176 { id = <N078>; range = <622121 626200>; rating = <0 0 0>; };
					tb177 { id = <N078>; range = <626201 627200>; rating = <40 0 0>; };
					tb178 { id = <N078>; range = <627201 627780>; rating = <40 40 0>; };
					tb179 { id = <N078>; range = <627781 628780>; rating = <0 40 0>; };
					tb180 { id = <N078>; range = <628781 631600>; rating = <0 0 0>; };
					tb181 { id = <N078>; range = <631601 633180>; rating = <0 0 2>; };
					tb182 { id = <N078>; range = <633181 637540>; rating = <0 0 0>; };
					tb183 { id = <N078>; range = <637541 638600>; rating = <2 0 0>; };
					tb184 { id = <N078>; range = <638601 639140>; rating = <2 2 0>; };
					tb185 { id = <N078>; range = <639141 640180>; rating = <0 2 0>; };
					tb186 { id = <N078>; range = <640181 653333>; rating = <0 0 0>; };
					tb187 { id = <N079>; range = <693334 697994>; rating = <0 0 0>; };
					tb188 { id = <N079>; range = <697995 699594>; rating = <0 0 2>; };
					tb189 { id = <N079>; range = <699595 705634>; rating = <0 0 0>; };
					tb190 { id = <N079>; range = <705635 706994>; rating = <2 0 0>; };
					tb191 { id = <N079>; range = <706995 707234>; rating = <2 2 0>; };
					tb192 { id = <N079>; range = <707235 708594>; rating = <0 2 0>; };
					tb193 { id = <N079>; range = <708595 709054>; rating = <0 0 0>; };
					tb194 { id = <N079>; range = <709055 710654>; rating = <0 0 40>; };
					tb195 { id = <N079>; range = <710655 716994>; rating = <0 0 0>; };
					tb196 { id = <N079>; range = <716995 718394>; rating = <40 0 0>; };
					tb197 { id = <N079>; range = <718395 718594>; rating = <40 40 0>; };
					tb198 { id = <N079>; range = <718595 719994>; rating = <0 40 0>; };
					tb199 { id = <N079>; range = <719995 720134>; rating = <0 0 0>; };
					tb200 { id = <N079>; range = <720135 721714>; rating = <0 0 2>; };
					tb201 { id = <N079>; range = <721715 728334>; rating = <0 0 0>; };
					tb202 { id = <N079>; range = <728335 729794>; rating = <2 0 0>; };
					tb203 { id = <N079>; range = <729795 729934>; rating = <2 2 0>; };
					tb204 { id = <N079>; range = <729935 731394>; rating = <0 2 0>; };
					tb205 { id = <N079>; range = <731395 733333>; rating = <0 0 0>; };
				};
			};
		};
	};
};
